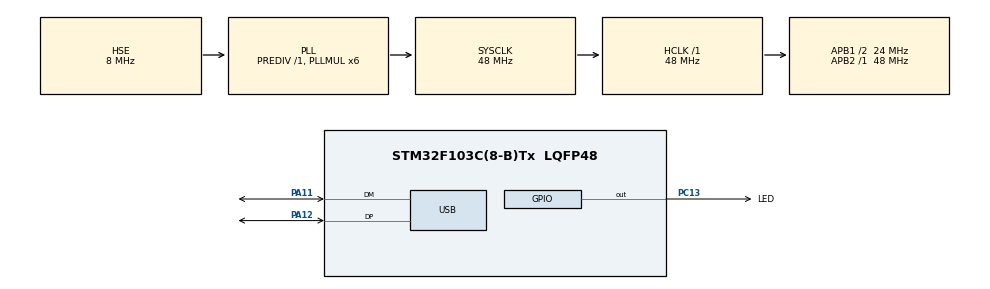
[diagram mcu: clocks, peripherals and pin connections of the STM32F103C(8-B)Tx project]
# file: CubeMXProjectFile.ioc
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FREERTOS.Queues01=queue0,16,uint16_t,0,Static,queue0Buffer,queue0ControlBlock
FREERTOS.Tasks01=defaultTask,24,128,StartDefaultTask,Default,NULL,Dynamic,NULL,NULL;blinkTask,24,128,StartTask02,Default,NULL,Dynamic,NULL,NULL
FREERTOS.Timers01=cyclicTimer0,cyclicTimer0Callback,osTimerPeriodic,Default,NULL,Dynamic,NULL
Mcu.Family=STM32F1
Mcu.Name=STM32F103C(8-B)Tx
Mcu.Package=LQFP48
NVIC.PriorityGroup=NVIC_PRIORITYGROUP_4
NVIC.TIM1_UP_IRQn=true\:15\:0\:false\:false\:true\:false\:false\:true\:true
NVIC.TimeBase=TIM1_UP_IRQn
NVIC.TimeBaseIP=TIM1
NVIC.USB_LP_CAN1_RX0_IRQn=true\:5\:0\:false\:false\:true\:true\:false\:true\:true
PA11.Mode=Device
PA11.Signal=USB_DM
PA12.Mode=Device
PA12.Signal=USB_DP
PA13.Mode=Serial_Wire
PA13.Signal=SYS_JTMS-SWDIO
PA14.Mode=Serial_Wire
PA14.Signal=SYS_JTCK-SWCLK
PC13-TAMPER-RTC.GPIO_Label=LED
PC13-TAMPER-RTC.PinState=GPIO_PIN_SET
PC13-TAMPER-RTC.Signal=GPIO_Output
PD0-OSC_IN.Mode=HSE-External-Oscillator
PD0-OSC_IN.Signal=RCC_OSC_IN
PD1-OSC_OUT.Mode=HSE-External-Oscillator
PD1-OSC_OUT.Signal=RCC_OSC_OUT
ProjectManager.HeapSize=0x200
ProjectManager.StackSize=0x400
ProjectManager.TargetToolchain=Makefile
RCC.AHBFreq_Value=48000000
RCC.APB1CLKDivider=RCC_HCLK_DIV2
RCC.APB1Freq_Value=24000000
RCC.APB1TimFreq_Value=48000000
RCC.APB2Freq_Value=48000000
RCC.APB2TimFreq_Value=48000000
RCC.HCLKFreq_Value=48000000
RCC.PLLMUL=RCC_PLL_MUL6
RCC.PLLSourceVirtual=RCC_PLLSOURCE_HSE
RCC.SYSCLKFreq_VALUE=48000000
RCC.SYSCLKSource=RCC_SYSCLKSOURCE_PLLCLK
RCC.USBFreq_Value=48000000
USB_DEVICE.CLASS_NAME_FS=CDC
USB_DEVICE.VirtualMode=Cdc
USB_DEVICE.VirtualModeFS=Cdc_FS
VP_FREERTOS_VS_CMSIS_V2.Mode=CMSIS_V2
VP_SYS_VS_tim1.Mode=TIM1
VP_USB_DEVICE_VS_USB_DEVICE_CDC_FS.Mode=CDC_FS
board=custom

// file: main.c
/* USER CODE BEGIN Header */
/**
  ******************************************************************************
  * @file           : main.c
  * @brief          : Main program body
  ******************************************************************************
  * @attention
  *
  * Copyright (c) 2023 STMicroelectronics.
  * All rights reserved.
  *
  * This software is licensed under terms that can be found in the LICENSE file
  * in the root directory of this software component.
  * If no LICENSE file comes with this software, it is provided AS-IS.
  *
  ******************************************************************************
  */
/* USER CODE END Header */
#include "main.h"
#include "cmsis_os.h"
#include "usb_device.h"

/* USER CODE BEGIN Includes */
#include <string.h>
#include "sm_ext.h"
#include "sm.h"
#include "sm_dbg.h"
#include "usbd_cdc_if.h"

/* USER CODE END Includes */

typedef StaticQueue_t osStaticMessageQDef_t;

/* USER CODE BEGIN PD */
//#define __DEBUG__
/* USER CODE END PD */

/* Definitions for defaultTask */
osThreadId_t defaultTaskHandle;
const osThreadAttr_t defaultTask_attributes = {
  .name = "defaultTask",
  .stack_size = 128 * 4,
  .priority = (osPriority_t) osPriorityNormal,
};
/* Definitions for blinkTask */
osThreadId_t blinkTaskHandle;
const osThreadAttr_t blinkTask_attributes = {
  .name = "blinkTask",
  .stack_size = 128 * 4,
  .priority = (osPriority_t) osPriorityNormal,
};
/* Definitions for queue0 */
osMessageQueueId_t queue0Handle;
uint8_t queue0Buffer[ 16 * sizeof( uint16_t ) ];
osStaticMessageQDef_t queue0ControlBlock;
const osMessageQueueAttr_t queue0_attributes = {
  .name = "queue0",
  .cb_mem = &queue0ControlBlock,
  .cb_size = sizeof(queue0ControlBlock),
  .mq_mem = &queue0Buffer,
  .mq_size = sizeof(queue0Buffer)
};
/* Definitions for cyclicTimer0 */
osTimerId_t cyclicTimer0Handle;
const osTimerAttr_t cyclicTimer0_attributes = {
  .name = "cyclicTimer0"
};
/* USER CODE BEGIN PV */
SM_INSTANCEDATA_T smInst=SM_INSTANCEDATA_INIT;
/* USER CODE END PV */

void SystemClock_Config(void);
static void MX_GPIO_Init(void);
void StartDefaultTask(void *argument);
void StartTask02(void *argument);
void cyclicTimer0Callback(void *argument);

int main(void)
{

  /* MCU Configuration--------------------------------------------------------*/

  /* Reset of all peripherals, Initializes the Flash interface and the Systick. */
  HAL_Init();

  /* Configure the system clock */
  SystemClock_Config();

  /* Initialize all configured peripherals */
  MX_GPIO_Init();

  /* Init scheduler */
  osKernelInitialize();

  /* Create the timer(s) */
  /* creation of cyclicTimer0 */
  cyclicTimer0Handle = osTimerNew(cyclicTimer0Callback, osTimerPeriodic, NULL, &cyclicTimer0_attributes);

  /* Create the queue(s) */
  /* creation of queue0 */
  queue0Handle = osMessageQueueNew (16, sizeof(uint16_t), &queue0_attributes);

  /* Create the thread(s) */
  /* creation of defaultTask */
  defaultTaskHandle = osThreadNew(StartDefaultTask, NULL, &defaultTask_attributes);

  /* creation of blinkTask */
  blinkTaskHandle = osThreadNew(StartTask02, NULL, &blinkTask_attributes);

  /* Start scheduler */
  osKernelStart();

  /* We should never get here as control is now taken by the scheduler */
  /* Infinite loop */
  while (1)
  {

  }
}

void SystemClock_Config(void)
{
  RCC_OscInitTypeDef RCC_OscInitStruct = {0};
  RCC_ClkInitTypeDef RCC_ClkInitStruct = {0};
  RCC_PeriphCLKInitTypeDef PeriphClkInit = {0};

  /** Initializes the RCC Oscillators according to the specified parameters
  * in the RCC_OscInitTypeDef structure.
  */
  RCC_OscInitStruct.OscillatorType = RCC_OSCILLATORTYPE_HSE;
  RCC_OscInitStruct.HSEState = RCC_HSE_ON;
  RCC_OscInitStruct.HSEPredivValue = RCC_HSE_PREDIV_DIV1;
  RCC_OscInitStruct.HSIState = RCC_HSI_ON;
  RCC_OscInitStruct.PLL.PLLState = RCC_PLL_ON;
  RCC_OscInitStruct.PLL.PLLSource = RCC_PLLSOURCE_HSE;
  RCC_OscInitStruct.PLL.PLLMUL = RCC_PLL_MUL6;
  if (HAL_RCC_OscConfig(&RCC_OscInitStruct) != HAL_OK)
  {
    Error_Handler();
  }

  /** Initializes the CPU, AHB and APB buses clocks
  */
  RCC_ClkInitStruct.ClockType = RCC_CLOCKTYPE_HCLK|RCC_CLOCKTYPE_SYSCLK
                              |RCC_CLOCKTYPE_PCLK1|RCC_CLOCKTYPE_PCLK2;
  RCC_ClkInitStruct.SYSCLKSource = RCC_SYSCLKSOURCE_PLLCLK;
  RCC_ClkInitStruct.AHBCLKDivider = RCC_SYSCLK_DIV1;
  RCC_ClkInitStruct.APB1CLKDivider = RCC_HCLK_DIV2;
  RCC_ClkInitStruct.APB2CLKDivider = RCC_HCLK_DIV1;

  if (HAL_RCC_ClockConfig(&RCC_ClkInitStruct, FLASH_LATENCY_1) != HAL_OK)
  {
    Error_Handler();
  }
  PeriphClkInit.PeriphClockSelection = RCC_PERIPHCLK_USB;
  PeriphClkInit.UsbClockSelection = RCC_USBCLKSOURCE_PLL;
  if (HAL_RCCEx_PeriphCLKConfig(&PeriphClkInit) != HAL_OK)
  {
    Error_Handler();
  }
}

static void MX_GPIO_Init(void)
{
  GPIO_InitTypeDef GPIO_InitStruct = {0};

  /* GPIO Ports Clock Enable */
  __HAL_RCC_GPIOC_CLK_ENABLE();
  __HAL_RCC_GPIOD_CLK_ENABLE();
  __HAL_RCC_GPIOA_CLK_ENABLE();

  /*Configure GPIO pin Output Level */
  HAL_GPIO_WritePin(LED_GPIO_Port, LED_Pin, GPIO_PIN_SET);

  /*Configure GPIO pin : LED_Pin */
  GPIO_InitStruct.Pin = LED_Pin;
  GPIO_InitStruct.Mode = GPIO_MODE_OUTPUT_PP;
  GPIO_InitStruct.Pull = GPIO_NOPULL;
  GPIO_InitStruct.Speed = GPIO_SPEED_FREQ_LOW;
  HAL_GPIO_Init(LED_GPIO_Port, &GPIO_InitStruct);

}

/* USER CODE BEGIN Header_StartDefaultTask */
/**
  * @brief  This is just a demo task that sends an event to the state machine
*           running in another task via message queue.
  * @param  argument: Not used
  * @retval None
  */
/* USER CODE END Header_StartDefaultTask */
void StartDefaultTask(void *argument)
{
  /* init code for USB_DEVICE */
  MX_USB_DEVICE_Init();
  /* USER CODE BEGIN 5 */

  osDelay(5000);
  uint16_t msg = evGoFailsafe;
  osStatus_t status = osMessageQueuePut(queue0Handle, &msg, 0U, osWaitForever);

  /* Infinite loop */
  for(;;)
  {
    osDelay(100);
  }
  /* USER CODE END 5 */
}

/* USER CODE BEGIN Header_StartTask02 */
/**
* @brief This tasks waits for events from the message queue and
        calls the state machine with this events.
* @param argument: Not used
* @retval None
*/
/* USER CODE END Header_StartTask02 */
void StartTask02(void *argument)
{
  /* USER CODE BEGIN StartTask02 */
  /* Infinite loop */

  uint16_t msg=SM_NO_MSG;

  sm(&smInst, msg); // call once with SM_NO_MSG to initialize the state machine

  for(;;)
  {
    osStatus_t status = osMessageQueueGet(queue0Handle, &msg, NULL, osWaitForever);

#ifdef __DEBUG__
    // Log new receveid event new message from queue
    char* dbgText;
    dbgText = smGetNameByEvent(msg);
    dbgText[strlen(dbgText)]='\n';
    // send debug text to USB port realizing a serial port
    uint8_t res = CDC_Transmit_FS((uint8_t*)dbgText, strlen(dbgText));
#endif

    // call state machine with new message from queue
    sm(&smInst, msg);
  }
  /* USER CODE END StartTask02 */
}

/* cyclicTimer0Callback function.  2*/
void cyclicTimer0Callback(void *argument)
{
  /* USER CODE BEGIN cyclicTimer0Callback */
  /* Each time this callback is called it puts an evTimeout into
     the message queue processed by task */
  uint16_t msg=evTimeout;
  osStatus_t status = osMessageQueuePut(queue0Handle, &msg, 0U, osWaitForever);
  /* USER CODE END cyclicTimer0Callback */
}

void HAL_TIM_PeriodElapsedCallback(TIM_HandleTypeDef *htim)
{
  if (htim->Instance == TIM1) {
    HAL_IncTick();
  }
}

void Error_Handler(void)
{
  __disable_irq();
  while (1)
  {
  }
}
